# GD32H71x_72x register map
File version: 1.0
CPU: CM7 r1p2, little endian, MPU, FPU, 4 interrupt priority bits
Registers are 32-bit, read-write, reset 0x0 unless marked. A register's access mark holds for its fields unless they carry their own. Offsets are from the block's base; [hi:lo] are bit positions; {n}, {i} and the like mark numbered series; 'fields as' and 'values as' point back to an identical list.

## AFMT0 — A-format encoder interface module
Base 0x4000C400
Same registers: AFMT1 0x40001800
{0x0+0x10*i} ENC{i}RDATA0 ro (i=0..7) — AFMT encoder {i} received data 0 register
  [31:0] RDATA — Received data from encoder {i}
{0x4+0x10*i} ENC{i}RDATA1 ro (i=0..7) — AFMT encoder {i} received data 1 register
  [31:0] RDATA — Received data from encoder {i}
{0x8+0x10*i} ENC{i}RDATA2 ro (i=0..7) — AFMT encoder {i} received data 2 register
  [31:0] RDATA — Received data from encoder {i}
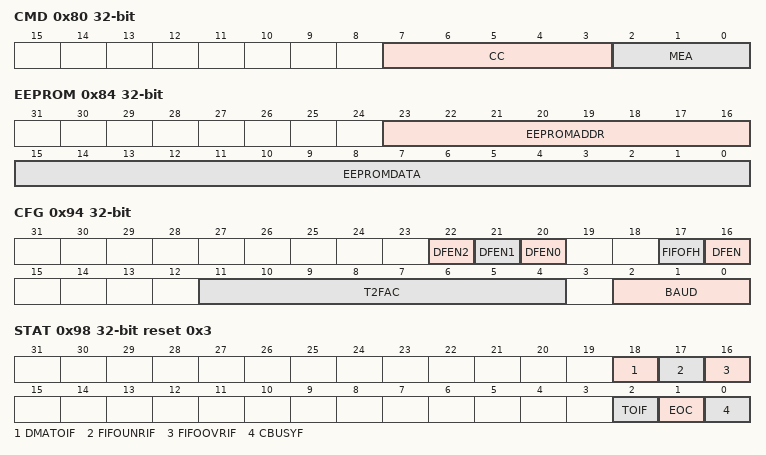
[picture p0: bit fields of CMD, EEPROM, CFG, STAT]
0x80 CMD — AFMT command register
  [7:3] CC — Encoder receive communication command code of A-format
  [2:0] MEA — Matching address of encoder
0x84 EEPROM — AFMT EEPROM register
  [23:16] EEPROMADDR — EEPROM accessing address of encoder
  [15:0] EEPROMDATA — Data to be writtern into EEPROM of encoder
0x88 IDCODE — AFMT ID code register
  [23:0] IDCODE — ID code for communication
0x8C TRGM — AFMT trigger mode register
  [0] TRANSTSEL — Transmission start trigger selection
0x90 SWT — AFMT software trigger register
  [0] SWTR — Data transmission software trigger, cleared by hardware
0x94 CFG access per field — AFMT configuration register
  [22] DFEN2 rw — DMA request and FIFO enable for EDIM_AFMT_ENCnRDATA2 register of active encoder
  [21] DFEN1 rw — DMA request and FIFO enable for EDIM_AFMT_ENCnRDATA1 register of active encoder
  [20] DFEN0 rw — DMA request and FIFO enable for EDIM_AFMT_ENCnRDATA0 register of active encoder n
  [17] FIFOFH wo — FIFO flush
  [16] DFEN rw — DMA request and FIFO enable
  [11:4] T2FAC rw — Time step factor of t2
  [2:0] BAUD rw — Communication baud rate configuration
0x98 STAT access per field reset 0x3 — AFMT status register
  [18] DMATOIF rw — DMA request timeout error interrupt flag
  [17] FIFOUNRIF rw — FIFO underrun error interrupt flag
  [16] FIFOOVRIF rw — FIFO overrun error interrupt flag
  [2] TOIF rw — Timeout error interrupt flag
  [1] EOC ro — End of communitcation
  [0] CBUSYF ro — Communitcation busy flag
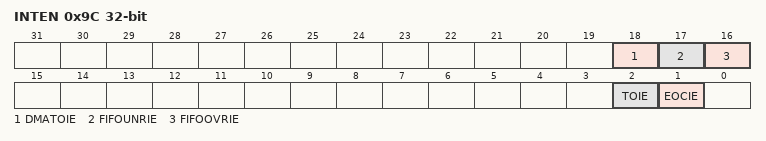
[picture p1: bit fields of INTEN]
0x9C INTEN — AFMT interrupt enable register
  [18] DMATOIE — Interrupt enable of DMATOIF
  [17] FIFOUNRIE — Interrupt enable of FIFOUNRIF
  [16] FIFOOVRIE — Interrupt enable of FIFOOVRIF
  [2] TOIE — Interrupt enable of TOIF
  [1] EOCIE — Interrupt enable of EOC
0x140 FIFODATA ro — AFMT FIFO data register
  [31:0] FIFODATA — FIFO data from EDIM_AFMT_ENCnRDATAm registers

## AXI — System and memory architecture
Base 0x51000000
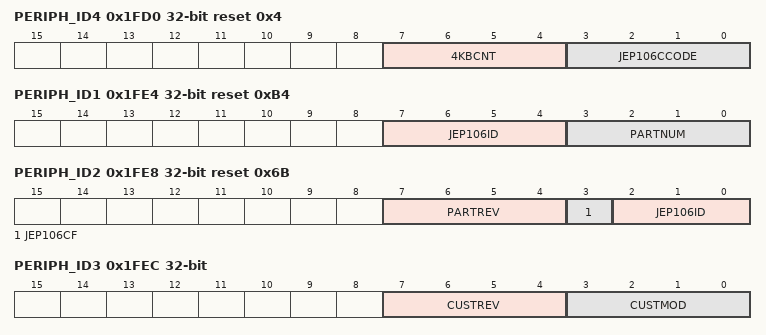
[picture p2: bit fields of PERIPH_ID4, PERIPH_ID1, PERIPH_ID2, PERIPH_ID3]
0x1FD0 PERIPH_ID4 ro reset 0x4 — AXI peripheral ID4 register
  [7:4] 4KBCNT — 4KB count
  [3:0] JEP106CCODE — JEP106 continuation code
0x1FE0 PERIPH_ID0 ro — AXI peripheral ID0 register
  [7:0] PARTNUM — Part number[7:0]
0x1FE4 PERIPH_ID1 ro reset 0xB4 — AXI peripheral ID1 register
  [7:4] JEP106ID — JEP106 Identity[3:0]
  [3:0] PARTNUM — Part number[11:8]
0x1FE8 PERIPH_ID2 ro reset 0x6B — AXI peripheral ID2 register
  [7:4] PARTREV — Part revision
  [3] JEP106CF — JEP106 code flag
  [2:0] JEP106ID — Part number[6:4]
0x1FEC PERIPH_ID3 ro — AXI peripheral ID3 register
  [7:4] CUSTREV — Customer version
  [3:0] CUSTMOD — Customer modification
0x1FF0 COMP_ID0 ro reset 0xD — AXI component ID0 register
  [7:0] PREAMB — Preamble bits
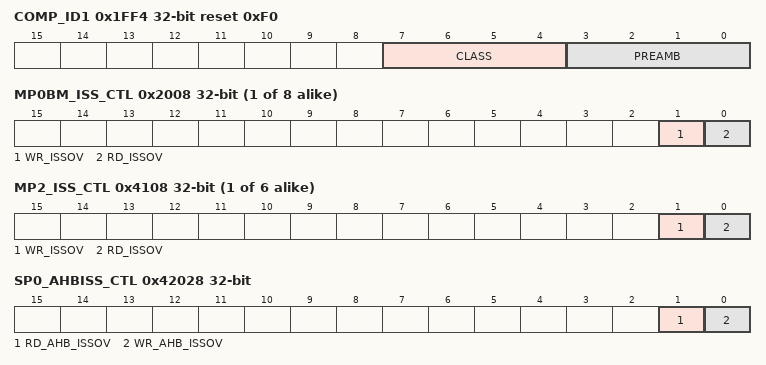
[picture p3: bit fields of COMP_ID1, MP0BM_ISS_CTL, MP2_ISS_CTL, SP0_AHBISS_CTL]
0x1FF4 COMP_ID1 ro reset 0xF0 — AXI component ID1 register
  [7:4] CLASS — Component class
  [3:0] PREAMB — Preamble bits
0x1FF8 COMP_ID2 ro reset 0x5 — AXI component ID2 register
  [7:0] PREAMB — Preamble bits
0x1FFC COMP_ID3 ro reset 0xB1 — AXI component ID3 register
  [7:0] PREAMB — Preamble bits
{0x2008+0x1000*i} MP{i}BM_ISS_CTL (i=0..7) — AXI master port {i} bus matrix issuing functionality control regist
  [1] WR_ISSOV — Override target write issuing function
  [0] RD_ISSOV — Override target read issuing function
0x2024 MP0BM_CTL — AXI Master Port 0 bus matrix functionality control regist
  [0] BPDIS — Beats packing function disable configure
0x202C MP0_LB_CTL — AXI Master Port 0 long burst functionality control regist
  [0] LBEN — Control long burst function
0x3024 MP1BM_CTL — AXI Master Port 1 bus matrix functionality control regist
  [0] BPDIS — Beats packing function disable configure
0x302C MP1_LB_CTL — AXI Master Port 1 long burst functionality control regist
  [0] LBEN — Control long burst function
{0x2108+0x1000*i} MP{i}_ISS_CTL (i=2..7) — AXI master port {i} issuing functionality control regist
  [1] WR_ISSOV — Override AMIB write issuing function
  [0] RD_ISSOV — Override AMIB read issuing function
0x8024 MP6BM_CTL — AXI Master Port 6 bus matrix functionality control regist
  [0] BPDIS — Beats packing function disable configure
0x9024 MP7BM_CTL — AXI Master Port 7 bus matrix functionality control regist
  [0] BPDIS — Beats packing function disable configure
0x42024 SP0_CTL — AXI slave port 0 functionality control regist
  [0] TRANSALT — Transaction alteration configure
0x42028 SP0_AHBISS_CTL — AXI slave port 0 AHB issuing functionality control regist
  [1] RD_AHB_ISSOV — Converts AHB-Lite read transaction to single beat AXI transaction function
  [0] WR_AHB_ISSOV — Converts AHB-Lite write transaction to single beat AXI transaction function
{0x42100+0x1000*i} SP{i}_RDQOS_CTL (i=0..4) — AXI slave port {i} read QOS control regist
  [3:0] RDQOS — Read channel QoS configure
{0x42104+0x1000*i} SP{i}_WRQOS_CTL (i=0..4) — AXI slave port {i} write QOS control regist
  [3:0] WRQOS — Write channel QoS configure
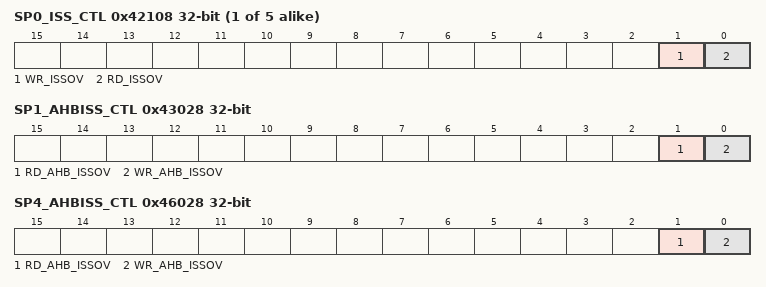
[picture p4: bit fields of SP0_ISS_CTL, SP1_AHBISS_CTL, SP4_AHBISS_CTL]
{0x42108+0x1000*i} SP{i}_ISS_CTL (i=0..4) — AXI slave port {i} issuing functionality control regist
  [1] WR_ISSOV — Override ASIB write issuing function
  [0] RD_ISSOV — Override ASIB read issuing function
0x43024 SP1_CTL — AXI slave port 1 functionality control regist
  [0] TRANSALT — Transaction alteration configure
0x43028 SP1_AHBISS_CTL — AXI slave port 1 AHB issuing functionality control regist
  fields as SP0_AHBISS_CTL
0x46024 SP4_CTL — AXI slave port 4 functionality control regist
  [0] TRANSALT — Transaction alteration configure
0x46028 SP4_AHBISS_CTL — AXI slave port 4 AHB issuing functionality control regist
  fields as SP0_AHBISS_CTL
